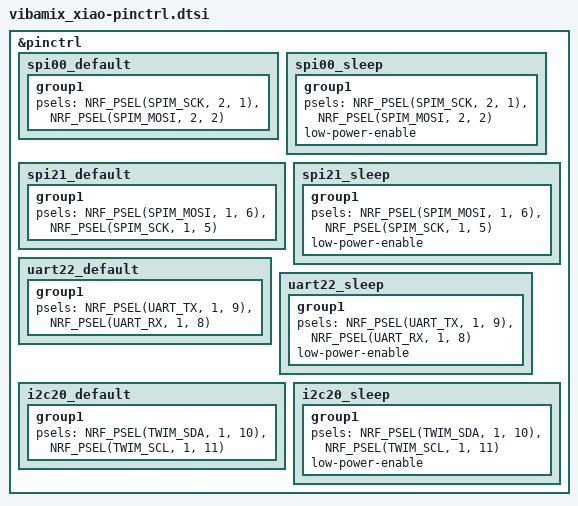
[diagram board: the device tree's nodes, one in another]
#include <dt-bindings/pinctrl/nrf-pinctrl.h>

&pinctrl {
	/* ePaper display on high-speed SPI00 - MISO omitted, display is write-only.
	 * spi00 (not spi20) so SERIAL20 stays free for the i2c20 light sensor; pins
	 * are unchanged (spi00 natively reaches P2.01/P2.02).
	 */
	spi00_default: spi00_default {
		group1 {
			psels = <NRF_PSEL(SPIM_SCK,  2, 1)>,	/* P2.01 SPI_CLK  */
				<NRF_PSEL(SPIM_MOSI, 2, 2)>;	/* P2.02 SPI_MOSI */
		};
	};

	spi00_sleep: spi00_sleep {
		group1 {
			psels = <NRF_PSEL(SPIM_SCK,  2, 1)>,
				<NRF_PSEL(SPIM_MOSI, 2, 2)>;
			low-power-enable;
		};
	};

	/* WS2812 LED strip on SPI21 - SCK routed to NC P1.05, only MOSI (DIN) is wired */
	spi21_default: spi21_default {
		group1 {
			psels = <NRF_PSEL(SPIM_MOSI, 1, 6)>,	/* P1.06 LED_DIN */
				<NRF_PSEL(SPIM_SCK,  1, 5)>;	/* P1.05 NC      */
		};
	};

	spi21_sleep: spi21_sleep {
		group1 {
			psels = <NRF_PSEL(SPIM_MOSI, 1, 6)>,
				<NRF_PSEL(SPIM_SCK,  1, 5)>;
			low-power-enable;
		};
	};


	/* UART22 - logging */
	uart22_default: uart22_default {
		group1 {
			psels = <NRF_PSEL(UART_TX, 1, 9)>,	/* P1.09 UART_TX */
				<NRF_PSEL(UART_RX, 1, 8)>;	/* P1.08 UART_RX */
		};
	};

	uart22_sleep: uart22_sleep {
		group1 {
			psels = <NRF_PSEL(UART_TX, 1, 9)>,
				<NRF_PSEL(UART_RX, 1, 8)>;
			low-power-enable;
		};
	};

	/* Light sensor I2C bus (SERIAL20) - free now that the ePaper moved to spi00 */
	i2c20_default: i2c20_default {
		group1 {
			psels = <NRF_PSEL(TWIM_SDA, 1, 10)>,	/* P1.10 LIGHT_SENSOR_SDA */
				<NRF_PSEL(TWIM_SCL, 1, 11)>;	/* P1.11 LIGHT_SENSOR_SCL */
		};
	};

	i2c20_sleep: i2c20_sleep {
		group1 {
			psels = <NRF_PSEL(TWIM_SDA, 1, 10)>,
				<NRF_PSEL(TWIM_SCL, 1, 11)>;
			low-power-enable;
		};
	};
};
